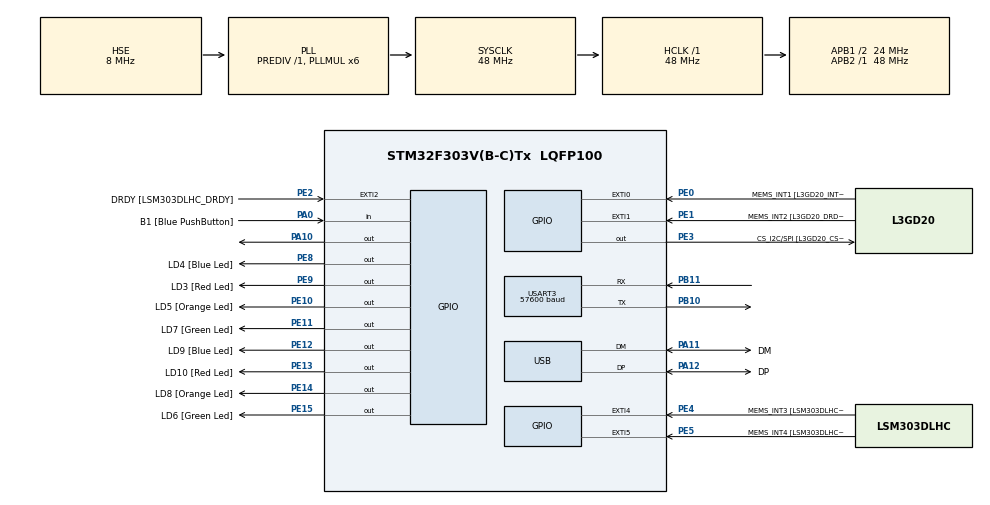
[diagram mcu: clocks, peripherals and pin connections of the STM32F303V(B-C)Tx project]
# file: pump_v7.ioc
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Mcu.Family=STM32F3
NVIC.USART3_IRQn=true\:0\:0\:false\:false\:true\:true\:true
USART3.MSBFirstParam=ADVFEATURE_MSBFIRST_DISABLE
RCC.CortexFreq_Value=48000000
PB10.Mode=Asynchronous
PE11.GPIO_Label=LD7 [Green Led]
PA14.GPIO_Label=SWCLK
RCC.SYSCLKSourceVirtual=RCC_SYSCLKSOURCE_PLLCLK
PA0.GPIO_Label=B1 [Blue PushButton]
PA11.Mode=Device
PA6.GPIO_Label=SPI1_MISO [L3GD20_SA0/SDO]
PB6.GPIO_Label=I2C1_SCL [LSM303DLHC_SCL]
PB11.Signal=USART3_RX
PC15-OSC32_OUT.GPIO_Label=OSC32_OUT
ProjectManager.StackSize=0x400
USART3.VirtualMode-Asynchronous=VM_ASYNC
PA12.Signal=USB_DP
USART3.BaudRate=57600
RCC.HCLKFreq_Value=48000000
RCC.APB2TimFreq_Value=48000000
PB6.Signal=I2C1_SCL
PE5.Signal=GPXTI5
PE1.Signal=GPXTI1
RCC.AHBFreq_Value=48000000
RCC.HSE_VALUE=8000000
PF0-OSC_IN.GPIO_Label=OSC_IN
RCC.PLLMUL=RCC_PLL_MUL6
PE13.Signal=GPIO_Output
PE9.Signal=GPIO_Output
PA14.Mode=Serial_Wire
PE4.GPIO_Label=MEMS_INT3 [LSM303DLHC_INT1]
PE2.Signal=GPXTI2
PB7.Signal=I2C1_SDA
PE10.Signal=GPIO_Output
PE4.Signal=GPXTI4
PA0.Signal=GPIO_Input
PB7.GPIO_Label=I2C1_SDA [LSM303DLHC_SDA]
Mcu.Package=LQFP100
PA6.Signal=SPI1_MISO
PA10.Signal=GPIO_Output
PE12.GPIO_Label=LD9 [Blue Led]
PE0.GPIO_Label=MEMS_INT1 [L3GD20_INT1]
RCC.APB1TimFreq_Value=48000000
USART3.DataInvertParam=ADVFEATURE_DATAINV_DISABLE
PC14-OSC32_IN.GPIO_Label=OSC32_IN
PE10.GPIO_Label=LD5 [Orange Led]
PE2.GPIO_Label=DRDY [LSM303DLHC_DRDY]
PF1-OSC_OUT.Signal=RCC_OSC_OUT
PB3.GPIO_Label=SWO
USART3.RxPinLevelInvertParam=ADVFEATURE_RXINV_DISABLE
PE4.GPIO_ModeDefaultEXTI=GPIO_MODE_EVT_RISING
PA11.GPIO_Label=DM
PE14.GPIO_Label=LD8 [Orange Led]
PE1.GPIO_ModeDefaultEXTI=GPIO_MODE_EVT_RISING
RCC.APB1CLKDivider=RCC_HCLK_DIV2
PC14-OSC32_IN.Signal=RCC_OSC32_IN
PA12.GPIO_Label=DP
PA13.Signal=SYS_JTMS-SWDIO
PE15.GPIO_Label=LD6 [Green Led]
PB11.Mode=Asynchronous
ProjectManager.TargetToolchain=STM32CubeIDE
PE5.GPIO_ModeDefaultEXTI=GPIO_MODE_EVT_RISING
PE0.GPIO_ModeDefaultEXTI=GPIO_MODE_EVT_RISING
PE8.GPIO_Label=LD4 [Blue Led]
RCC.USBFreq_Value=48000000
PE11.Signal=GPIO_Output
RCC.LSE_VALUE=32768
PC15-OSC32_OUT.Signal=RCC_OSC32_OUT
PE9.GPIO_Label=LD3 [Red Led]
PF0-OSC_IN.Mode=HSE-External-Clock-Source
PB10.Signal=USART3_TX
USART3.TxPinLevelInvertParam=ADVFEATURE_TXINV_DISABLE
PA5.Signal=SPI1_SCK
board=STM32F3DISCOVERY
PE1.GPIO_Label=MEMS_INT2 [L3GD20_DRDY/INT2]
USART3.WordLength=WORDLENGTH_9B
RCC.APB2Freq_Value=48000000
PE14.Signal=GPIO_Output
PE15.Signal=GPIO_Output
PE8.Signal=GPIO_Output
PF1-OSC_OUT.GPIO_Label=OSC_OUT
PA13.Mode=Serial_Wire
Mcu.Name=STM32F303V(B-C)Tx
PE0.Signal=GPXTI0
PE12.Signal=GPIO_Output
PA13.GPIO_Label=SWDIO
PB3.Signal=SYS_JTDO-TRACESWO
RCC.SYSCLKFreq_VALUE=48000000
PA7.GPIO_Label=SPI1_MISO [L3GD20_SDA/SDI/SDO]
PE13.GPIO_Label=LD10 [Red Led]
PA12.Mode=Device
PA5.GPIO_Label=SPI1_SCK [L3GD20_SCL/SPC]
PE5.GPIO_Label=MEMS_INT4 [LSM303DLHC_INT2]
PA11.Signal=USB_DM
PA14.Signal=SYS_JTCK-SWCLK
ProjectManager.HeapSize=0x200
RCC.HSI_VALUE=8000000
NVIC.PriorityGroup=NVIC_PRIORITYGROUP_0
PE3.Signal=GPIO_Output
PE3.GPIO_Label=CS_I2C/SPI [L3GD20_CS_I2C/SPI]
PE2.GPIO_ModeDefaultEXTI=GPIO_MODE_EVT_RISING
PF0-OSC_IN.Signal=RCC_OSC_IN
RCC.APB1Freq_Value=24000000
PA7.Signal=SPI1_MOSI
USART3.Parity=PARITY_EVEN

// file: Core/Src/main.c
/* USER CODE BEGIN Header */
/**
  ******************************************************************************
  * @file           : main.c
  * @brief          : Main program body
  ******************************************************************************
  * @attention
  *
  * <h2><center>&copy; Copyright (c) 2021 STMicroelectronics.
  * All rights reserved.</center></h2>
  *
  * This software component is licensed by ST under BSD 3-Clause license,
  * the "License"; You may not use this file except in compliance with the
  * License. You may obtain a copy of the License at:
  *                        opensource.org/licenses/BSD-3-Clause
  *
  ******************************************************************************
  */
/* USER CODE END Header */
#include "main.h"

/* USER CODE BEGIN Includes */
#include "modbus_stm.h"
/* USER CODE END Includes */

UART_HandleTypeDef huart3;

PCD_HandleTypeDef hpcd_USB_FS;

void SystemClock_Config(void);
static void MX_GPIO_Init(void);
static void MX_USB_PCD_Init(void);
static void MX_USART3_UART_Init(void);

int main(void)
{

  /* MCU Configuration--------------------------------------------------------*/

  /* Reset of all peripherals, Initializes the Flash interface and the Systick. */
  HAL_Init();

  /* Configure the system clock */
  SystemClock_Config();

  /* Initialize all configured peripherals */
  MX_GPIO_Init();
  MX_USB_PCD_Init();
  MX_USART3_UART_Init();

  /* Infinite loop */
  /* USER CODE BEGIN WHILE */
  //while (1)
  //{
    /* USER CODE END WHILE */

    /* USER CODE BEGIN 3 */
	/*  READ_HOLDING_REG(0x40,0x07,0x00,0x01);
	  READ_HOLDING_REG(0x40,0x05,0x00,0x02);
	  READ_HOLDING_REG(0x40,0x06,0x00,0x03);
	  READ_INPUT_REG(0x40,0x00,0x00,0x00);
	  READ_INPUT_REG(0x40,0x00,0x00,0x01);
	  READ_INPUT_REG(0x40,0x05,0x00,0x01);
*/
//	  WRITE_SINGLE_REG(0x40,0x01,5);

//	 	  	for(int k =0;k<80;k++)
//	 	  		write_reg_map[k]=54;
//	 	  	WRITE_MULTI_REG(0x5B,0x00,0x00,3);
  	  write_reg_map[0]=0;
  	  write_reg_map[1]=2;
  	  write_reg_map[2]=0x07;
  	  write_reg_map[3]=0xD0;
  	WRITE_MULTI_REG(0x40,0x00,0x00,2);

  	READ_INPUT_REG(0x40,0x01,0x00,0x01);
  	READ_INPUT_REG(0x40,0x11,0x00,0x01);

  	READ_INPUT_REG(0x40,0x07,0x00,0x05);
  	//HAL_Delay(10000);
  	 write_reg_map[0]=0;
  	  	  write_reg_map[1]=1;
  	  	  write_reg_map[2]=0;
  	  	  write_reg_map[3]=0;
  	  	WRITE_MULTI_REG(0x40,0x00,0x00,2);
//	 	  	CHANGE_STATE(2);
//	 	  	GET_STATE();
//	 	  	CHANGE_STATE(3);
//	 	  	GET_STATE();
  //}
  /* USER CODE END 3 */
}

void SystemClock_Config(void)
{
  RCC_OscInitTypeDef RCC_OscInitStruct = {0};
  RCC_ClkInitTypeDef RCC_ClkInitStruct = {0};
  RCC_PeriphCLKInitTypeDef PeriphClkInit = {0};

  /** Initializes the RCC Oscillators according to the specified parameters
  * in the RCC_OscInitTypeDef structure.
  */
  RCC_OscInitStruct.OscillatorType = RCC_OSCILLATORTYPE_HSE;
  RCC_OscInitStruct.HSEState = RCC_HSE_BYPASS;
  RCC_OscInitStruct.HSEPredivValue = RCC_HSE_PREDIV_DIV1;
  RCC_OscInitStruct.HSIState = RCC_HSI_ON;
  RCC_OscInitStruct.PLL.PLLState = RCC_PLL_ON;
  RCC_OscInitStruct.PLL.PLLSource = RCC_PLLSOURCE_HSE;
  RCC_OscInitStruct.PLL.PLLMUL = RCC_PLL_MUL6;
  if (HAL_RCC_OscConfig(&RCC_OscInitStruct) != HAL_OK)
  {
    Error_Handler();
  }
  /** Initializes the CPU, AHB and APB buses clocks
  */
  RCC_ClkInitStruct.ClockType = RCC_CLOCKTYPE_HCLK|RCC_CLOCKTYPE_SYSCLK
                              |RCC_CLOCKTYPE_PCLK1|RCC_CLOCKTYPE_PCLK2;
  RCC_ClkInitStruct.SYSCLKSource = RCC_SYSCLKSOURCE_PLLCLK;
  RCC_ClkInitStruct.AHBCLKDivider = RCC_SYSCLK_DIV1;
  RCC_ClkInitStruct.APB1CLKDivider = RCC_HCLK_DIV2;
  RCC_ClkInitStruct.APB2CLKDivider = RCC_HCLK_DIV1;

  if (HAL_RCC_ClockConfig(&RCC_ClkInitStruct, FLASH_LATENCY_1) != HAL_OK)
  {
    Error_Handler();
  }
  PeriphClkInit.PeriphClockSelection = RCC_PERIPHCLK_USB|RCC_PERIPHCLK_USART3;
  PeriphClkInit.Usart3ClockSelection = RCC_USART3CLKSOURCE_PCLK1;
  PeriphClkInit.USBClockSelection = RCC_USBCLKSOURCE_PLL;
  if (HAL_RCCEx_PeriphCLKConfig(&PeriphClkInit) != HAL_OK)
  {
    Error_Handler();
  }
}

static void MX_USART3_UART_Init(void)
{

  huart3.Instance = USART3;
  huart3.Init.BaudRate = 57600;
  huart3.Init.WordLength = UART_WORDLENGTH_9B;
  huart3.Init.StopBits = UART_STOPBITS_1;
  huart3.Init.Parity = UART_PARITY_EVEN;
  huart3.Init.Mode = UART_MODE_TX_RX;
  huart3.Init.HwFlowCtl = UART_HWCONTROL_NONE;
  huart3.Init.OverSampling = UART_OVERSAMPLING_16;
  huart3.Init.OneBitSampling = UART_ONE_BIT_SAMPLE_DISABLE;
  huart3.AdvancedInit.AdvFeatureInit = UART_ADVFEATURE_NO_INIT;
  if (HAL_UART_Init(&huart3) != HAL_OK)
  {
    Error_Handler();
  }

}

static void MX_USB_PCD_Init(void)
{

  hpcd_USB_FS.Instance = USB;
  hpcd_USB_FS.Init.dev_endpoints = 8;
  hpcd_USB_FS.Init.speed = PCD_SPEED_FULL;
  hpcd_USB_FS.Init.phy_itface = PCD_PHY_EMBEDDED;
  hpcd_USB_FS.Init.low_power_enable = DISABLE;
  hpcd_USB_FS.Init.battery_charging_enable = DISABLE;
  if (HAL_PCD_Init(&hpcd_USB_FS) != HAL_OK)
  {
    Error_Handler();
  }

}

static void MX_GPIO_Init(void)
{
  GPIO_InitTypeDef GPIO_InitStruct = {0};

  /* GPIO Ports Clock Enable */
  __HAL_RCC_GPIOE_CLK_ENABLE();
  __HAL_RCC_GPIOC_CLK_ENABLE();
  __HAL_RCC_GPIOF_CLK_ENABLE();
  __HAL_RCC_GPIOA_CLK_ENABLE();
  __HAL_RCC_GPIOB_CLK_ENABLE();

  /*Configure GPIO pin Output Level */
  HAL_GPIO_WritePin(GPIOE, CS_I2C_SPI_Pin|LD4_Pin|LD3_Pin|LD5_Pin
                          |LD7_Pin|LD9_Pin|LD10_Pin|LD8_Pin
                          |LD6_Pin, GPIO_PIN_RESET);

  /*Configure GPIO pin Output Level */
  HAL_GPIO_WritePin(GPIOA, GPIO_PIN_10, GPIO_PIN_RESET);

  /*Configure GPIO pins : DRDY_Pin MEMS_INT3_Pin MEMS_INT4_Pin MEMS_INT1_Pin
                           MEMS_INT2_Pin */
  GPIO_InitStruct.Pin = DRDY_Pin|MEMS_INT3_Pin|MEMS_INT4_Pin|MEMS_INT1_Pin
                          |MEMS_INT2_Pin;
  GPIO_InitStruct.Mode = GPIO_MODE_EVT_RISING;
  GPIO_InitStruct.Pull = GPIO_NOPULL;
  HAL_GPIO_Init(GPIOE, &GPIO_InitStruct);

  /*Configure GPIO pins : CS_I2C_SPI_Pin LD4_Pin LD3_Pin LD5_Pin
                           LD7_Pin LD9_Pin LD10_Pin LD8_Pin
                           LD6_Pin */
  GPIO_InitStruct.Pin = CS_I2C_SPI_Pin|LD4_Pin|LD3_Pin|LD5_Pin
                          |LD7_Pin|LD9_Pin|LD10_Pin|LD8_Pin
                          |LD6_Pin;
  GPIO_InitStruct.Mode = GPIO_MODE_OUTPUT_PP;
  GPIO_InitStruct.Pull = GPIO_NOPULL;
  GPIO_InitStruct.Speed = GPIO_SPEED_FREQ_LOW;
  HAL_GPIO_Init(GPIOE, &GPIO_InitStruct);

  /*Configure GPIO pin : B1_Pin */
  GPIO_InitStruct.Pin = B1_Pin;
  GPIO_InitStruct.Mode = GPIO_MODE_INPUT;
  GPIO_InitStruct.Pull = GPIO_NOPULL;
  HAL_GPIO_Init(B1_GPIO_Port, &GPIO_InitStruct);

  /*Configure GPIO pins : SPI1_SCK_Pin SPI1_MISO_Pin SPI1_MISOA7_Pin */
  GPIO_InitStruct.Pin = SPI1_SCK_Pin|SPI1_MISO_Pin|SPI1_MISOA7_Pin;
  GPIO_InitStruct.Mode = GPIO_MODE_AF_PP;
  GPIO_InitStruct.Pull = GPIO_NOPULL;
  GPIO_InitStruct.Speed = GPIO_SPEED_FREQ_HIGH;
  GPIO_InitStruct.Alternate = GPIO_AF5_SPI1;
  HAL_GPIO_Init(GPIOA, &GPIO_InitStruct);

  /*Configure GPIO pin : PA10 */
  GPIO_InitStruct.Pin = GPIO_PIN_10;
  GPIO_InitStruct.Mode = GPIO_MODE_OUTPUT_PP;
  GPIO_InitStruct.Pull = GPIO_NOPULL;
  GPIO_InitStruct.Speed = GPIO_SPEED_FREQ_LOW;
  HAL_GPIO_Init(GPIOA, &GPIO_InitStruct);

  /*Configure GPIO pins : I2C1_SCL_Pin I2C1_SDA_Pin */
  GPIO_InitStruct.Pin = I2C1_SCL_Pin|I2C1_SDA_Pin;
  GPIO_InitStruct.Mode = GPIO_MODE_AF_OD;
  GPIO_InitStruct.Pull = GPIO_PULLUP;
  GPIO_InitStruct.Speed = GPIO_SPEED_FREQ_HIGH;
  GPIO_InitStruct.Alternate = GPIO_AF4_I2C1;
  HAL_GPIO_Init(GPIOB, &GPIO_InitStruct);

}

void Error_Handler(void)
{
  __disable_irq();
  while (1)
  {
  }
}

/************************ (C) COPYRIGHT STMicroelectronics *****END OF FILE****/
